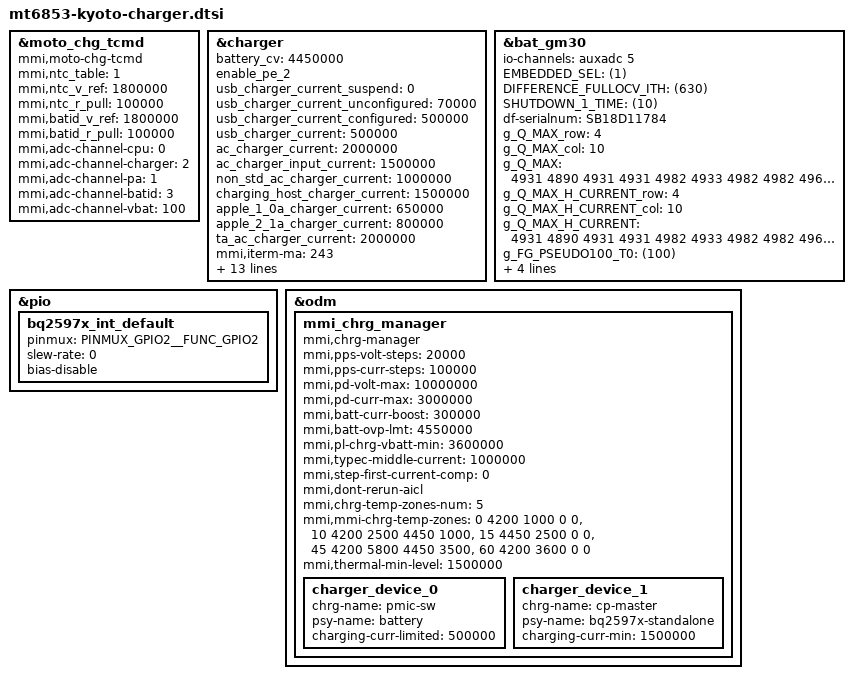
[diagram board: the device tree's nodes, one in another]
/*
 * Copyright (c) 2019 MediaTek Inc.
 *
 * This program is free software; you can redistribute it and/or modify
 * it under the terms of the GNU General Public License version 2 as
 * published by the Free Software Foundation.
 *
 * This program is distributed in the hope that it will be useful,
 * but WITHOUT ANY WARRANTY; without even the implied warranty of
 * MERCHANTABILITY or FITNESS FOR A PARTICULAR PURPOSE.  See the
 * GNU General Public License for more details.
 */

&moto_chg_tcmd {
                compatible = "mmi,moto-chg-tcmd";
                status = "okay";

                mmi,ntc_table = <1>;
                mmi,ntc_v_ref = <1800000>;
                mmi,ntc_r_pull = <100000>;

                mmi,batid_v_ref = <1800000>;
                mmi,batid_r_pull = <100000>;

                mmi,adc-channel-cpu = <0>;
                mmi,adc-channel-charger = <2>;
                mmi,adc-channel-pa = <1>;
                mmi,adc-channel-batid = <3>;
                mmi,adc-channel-vbat = <100>;
};

&charger {
        /* common */
        battery_cv = <4450000>;
	enable_pe_2;
        /* charging current */
        usb_charger_current_suspend = <0>;
        usb_charger_current_unconfigured = <70000>;
        usb_charger_current_configured = <500000>;
        usb_charger_current = <500000>;
        ac_charger_current = <2000000>;
        ac_charger_input_current = <1500000>;
        non_std_ac_charger_current = <1000000>;
        charging_host_charger_current = <1500000>;
        apple_1_0a_charger_current = <650000>;
        apple_2_1a_charger_current = <800000>;
        ta_ac_charger_current = <2000000>;

        /*mmi config*/
        mmi,iterm-ma = <243>;
        mmi,mmi-temp-zones = <0 4200 1000 0>,
                        <10 4200 2500 1000>,
                        <15 0 2500 2500>,
			<25 0 3000 3000>,
			<35 0 3000 3000>,
                        <45 0 3000 3000>,
                        <60 4200 3000 0>;
	mmi,mmi-ffc-zones = <4450 243>,
				<4450 243>,
				<4450 243>,
				<4480 509>,
				<4480 548>,
				<4480 563>,
				<4450 243>;
        mmi,enable-charging-limit;
        mmi,upper-limit-capacity = <65>;
        mmi,lower-limit-capacity = <60>;
        mmi,vfloat-comp-uv = <0>;
        max_charger_voltage = <11000000>;
	enable_cp;
};

&bat_gm30 {
        io-channels = <&auxadc 5>;
        io-channel-names = "batteryID-channel";
        EMBEDDED_SEL = <(1)>;   /* embedded battery.*/
        DIFFERENCE_FULLOCV_ITH = <(630)>;       /*Charging termination current.*/
	SHUTDOWN_1_TIME = <(10)>;

        df-serialnum = "SB18D11784";
	g_Q_MAX_row = <4>;
	g_Q_MAX_col = <10>;
	g_Q_MAX = <
		/*bat1,   bat2,   bat3,    bat4*/
		4931 4890 4931 4931/*T0*/
		4982 4933 4982 4982/*T1*/
		4969 4924 4897 4897/*T2*/
		4975 4859 4308 4308/*T3*/
		4905 4783 3488 3488/*T4*/
		3488 3488 3488 3488/*T5*/
		3488 3488 3488 3488/*T6*/
		3488 3488 3488 3488/*T7*/
		3488 3488 3488 3488/*T8*/
		3488 3488 3488 3488/*T9*/
	>;
	g_Q_MAX_H_CURRENT_row = <4>;
	g_Q_MAX_H_CURRENT_col = <10>;
	g_Q_MAX_H_CURRENT = <
		/*bat1,   bat2,   bat3,    bat4*/
		4931 4890 4931 4931/*T0*/
		4982 4933 4982 4982/*T1*/
		4969 4924 4897 4897/*T2*/
		4975 4859 4308 4308/*T3*/
		4905 4783 3488 3488/*T4*/
		3488 3488 3488 3488/*T5*/
		3488 3488 3488 3488/*T6*/
		3488 3488 3488 3488/*T7*/
		3488 3488 3488 3488/*T8*/
		3488 3488 3488 3488/*T9*/
	>;

	g_FG_PSEUDO100_T0 = <(100)>;
	/*Pseudo 100% percentage at T0*/
	g_FG_PSEUDO100_T1 = <(100)>;
	/*Pseudo 100% percentage at T1*/
	g_FG_PSEUDO100_T2 = <(90)>;
	/*Pseudo 100% percentage at T2*/
	g_FG_PSEUDO100_T3 = <(84)>;
	/*Pseudo 100% percentage at T3*/
	g_FG_PSEUDO100_T4 = <(63)>;
	/*Pseudo 100% percentage at T4*/

        #include "bat_setting/batterytable_nt50_atl_5000mah_ext.dtsi"
	#include "bat_setting/batterytable_nt50_sunwoda_5000mah_ext.dtsi"
};

&pio {
	bq2597x_int_default: bq2597x_int_default {
		pinmux = <PINMUX_GPIO2__FUNC_GPIO2>;
		slew-rate= <0>;
		bias-disable;
	};
};

&odm {
	mmi_chrg_manager {
		compatible = "mmi,chrg-manager";
		mmi,pps-volt-steps = <20000>;
		mmi,pps-curr-steps = <100000>;
		mmi,pd-volt-max = <10000000>;
		mmi,pd-curr-max = <3000000>;
		mmi,batt-curr-boost = <300000>;
		mmi,batt-ovp-lmt = <4550000>;
		mmi,pl-chrg-vbatt-min = <3600000>;
		mmi,typec-middle-current = <1000000>;
		mmi,step-first-current-comp = <0>;
		mmi,dont-rerun-aicl;
		mmi,chrg-temp-zones-num = <5>;
		mmi,mmi-chrg-temp-zones =
					<0 4200 1000  0 0>,
					<10 4200 2500 4450 1000>,
					<15 4450 2500 0 0>,
					<45 4200 5800 4450 3500>,
					<60 4200 3600 0 0>;
		mmi,thermal-min-level = <1500000>;
		charger_device_0 {
			chrg-name = "pmic-sw";
			psy-name = "battery";
			charging-curr-limited = <500000>;
		};
		charger_device_1 {
			chrg-name = "cp-master";
			psy-name = "bq2597x-standalone";
			charging-curr-min = <1500000>;
		};
	};
};
